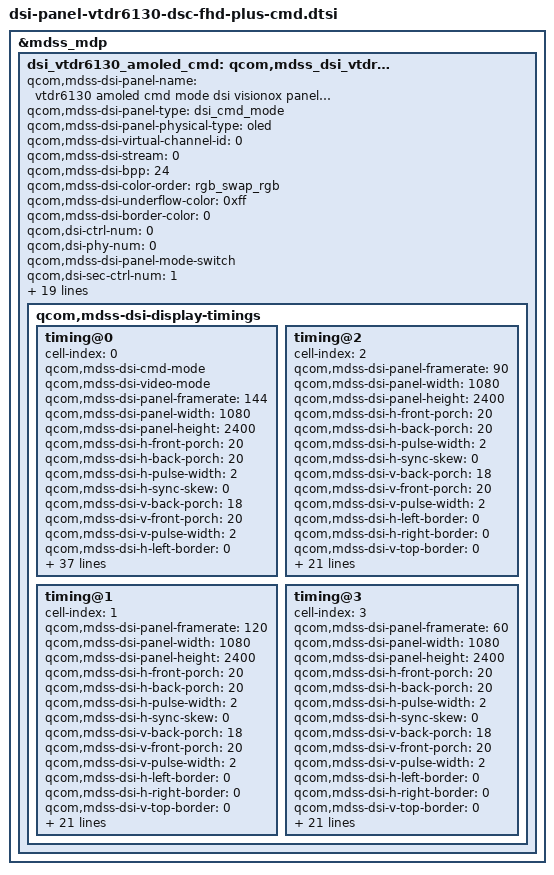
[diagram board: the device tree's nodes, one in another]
&mdss_mdp {
	dsi_vtdr6130_amoled_cmd: qcom,mdss_dsi_vtdr6130_fhd_plus_cmd {
		qcom,mdss-dsi-panel-name =
			"vtdr6130 amoled cmd mode dsi visionox panel with DSC";
		qcom,mdss-dsi-panel-type = "dsi_cmd_mode";
		qcom,mdss-dsi-panel-physical-type = "oled";
		qcom,mdss-dsi-virtual-channel-id = <0>;
		qcom,mdss-dsi-stream = <0>;
		qcom,mdss-dsi-bpp = <24>;
		qcom,mdss-dsi-color-order = "rgb_swap_rgb";
		qcom,mdss-dsi-underflow-color = <0xff>;
		qcom,mdss-dsi-border-color = <0>;

		qcom,dsi-ctrl-num = <0>;
		qcom,dsi-phy-num = <0>;
		qcom,mdss-dsi-panel-mode-switch;

		qcom,dsi-sec-ctrl-num = <1>;
		qcom,dsi-sec-phy-num = <1>;

		qcom,mdss-dsi-traffic-mode = "non_burst_sync_event";
		qcom,mdss-dsi-lane-map = "lane_map_0123";
		qcom,mdss-dsi-bllp-eof-power-mode;
		qcom,mdss-dsi-bllp-power-mode;
		qcom,mdss-dsi-lane-0-state;
		qcom,mdss-dsi-lane-1-state;
		qcom,mdss-dsi-lane-2-state;
		qcom,mdss-dsi-lane-3-state;
		qcom,mdss-dsi-dma-trigger = "trigger_sw";
		qcom,mdss-dsi-mdp-trigger = "none";
		qcom,mdss-dsi-reset-sequence = <1 10>, <0 10>, <1 10>;

		qcom,mdss-dsi-te-pin-select = <1>;
		qcom,mdss-dsi-wr-mem-start = <0x2c>;
		qcom,mdss-dsi-wr-mem-continue = <0x3c>;
		qcom,mdss-dsi-te-dcs-command = <1>;
		qcom,mdss-dsi-te-check-enable;
		qcom,mdss-dsi-te-using-te-pin;
		qcom,mdss-dsi-display-timings {
			timing@0 {
				cell-index = <0>;
				qcom,mdss-dsi-cmd-mode;
				qcom,mdss-dsi-video-mode;
				qcom,mdss-dsi-panel-framerate = <144>;
				qcom,mdss-dsi-panel-width = <1080>;
				qcom,mdss-dsi-panel-height = <2400>;
				qcom,mdss-dsi-h-front-porch = <20>;
				qcom,mdss-dsi-h-back-porch = <20>;
				qcom,mdss-dsi-h-pulse-width = <2>;
				qcom,mdss-dsi-h-sync-skew = <0>;
				qcom,mdss-dsi-v-back-porch = <18>;
				qcom,mdss-dsi-v-front-porch = <20>;
				qcom,mdss-dsi-v-pulse-width = <2>;
				qcom,mdss-dsi-h-left-border = <0>;
				qcom,mdss-dsi-h-right-border = <0>;
				qcom,mdss-dsi-v-top-border = <0>;
				qcom,mdss-dsi-v-bottom-border = <0>;
				qcom,mdss-dsi-panel-jitter = <0x4 0x1>;
				qcom,mdss-dsi-panel-clockrate = <847480320>;

				qcom,mdss-dsi-timing-switch-command = [
					39 01 00 00 00 00 02 6c 01
					39 01 00 00 00 00 03 f0 aa 10
					39 01 00 00 00 00 16 b1 01 38 00 14 00
					   1c 00 01 66 00 14 00 14 00 01 66 00
					   14 05 cc 00
					39 01 00 00 00 00 03 f0 aa 13
					39 01 00 00 00 00 18 ce 09 11 09 11 08
					   c1 07 fa 05 a4 00 3c 00 34 00 24 00
					   0c 00 0c 04 00 35
				];

				qcom,cmd-on-commands = [
					39 01 00 00 00 00 02 03 01
					39 01 00 00 00 00 02 35 00
					39 01 00 00 00 00 02 53 20
					39 01 00 00 00 00 03 51 00 00
					39 01 00 00 00 00 02 59 00
					39 01 00 00 00 00 02 6c 01
					39 01 00 00 00 00 02 6d 00
					39 01 00 00 00 00 02 6f 02
					39 01 00 00 00 00 5f 70 12 00 00 ab 30
					   80 09 60 04 38 00 28 02 1c 02 1c 02
					   00 02 0e 00 20 03 dd 00 07 00 0c 02
					   77 02 8b 18 00 10 f0 07 10 20 00 06
					   0f 0f 33 0e 1c 2a 38 46 54 62 69 70
					   77 79 7b 7d 7e 02 02 22 00 2a 40 2a
					   be 3a fc 3a fa 3a f8 3b 38 3b 78 3b
					   b6 4b b6 4b f4 4b f4 6c 34 84 74 00
					   00 00 00 00 00
					39 01 00 00 00 00 03 f0 aa 10
					39 01 00 00 00 00 02 65 16
					39 01 00 00 00 00 03 EB 00 00
					39 01 00 00 00 00 16 b1 01 38 00 14 00
					   1c 00 01 66 00 14 00 14 00 01 66 00
					   14 05 cc 00
					39 01 00 00 00 00 03 f0 aa 13
					39 01 00 00 00 00 18 ce 09 11 09 11 08
					   c1 07 fa 05 a4 00 3c 00 34 00 24 00
					   0c 00 0c 04 00 35
					39 01 00 00 00 00 03 f0 aa 14
					39 01 00 00 00 00 03 b2 03 33
					39 01 00 00 00 00 0d b4 00 33 00 00 00
					   3e 00 00 00 3e 00 00
					39 01 00 00 00 00 0a b5 00 09 09 09 09
					   09 09 06 01
					39 01 00 00 00 00 07 b9 00 00 08 09 09
					   09
					39 01 00 00 00 00 0d bc 10 00 00 06 11
					   09 3b 09 47 09 47 00
					39 01 00 00 00 00 0d be 10 10 00 08 22
					   09 19 09 25 09 25 00
					39 01 00 00 00 00 03 ff 5a 80
					39 01 00 00 00 00 02 65 14
					39 01 00 00 00 00 04 fa 08 08 08
					39 01 00 00 00 00 03 ff 5a 81
					39 01 00 00 00 00 02 65 05
					39 01 00 00 00 00 02 f3 0f
					39 01 00 00 00 00 03 f0 aa 00
					39 01 00 00 00 00 03 ff 5a 82
					39 01 00 00 00 00 02 f9 00
					39 01 00 00 00 00 03 ff 51 83
					39 01 00 00 00 00 02 65 04
					39 01 00 00 00 00 02 f8 00
					39 01 00 00 00 00 03 ff 5a 00
					39 01 00 00 00 00 02 65 01
					39 01 00 00 00 00 02 f4 9a
					39 01 00 00 00 00 03 ff 5a 00
					05 01 00 00 78 00 01 11
					05 01 00 00 14 00 01 29
				];

				qcom,vid-on-commands = [
					39 01 00 00 00 00 02 03 01
					39 01 00 00 00 00 02 35 00
					39 01 00 00 00 00 02 53 20
					39 01 00 00 00 00 03 51 00 00
					39 01 00 00 00 00 02 59 00
					39 01 00 00 00 00 02 6C 01
					39 01 00 00 00 00 02 6D 00
					39 01 00 00 00 00 02 6F 01
					39 01 00 00 00 00 5F 70 12 00 00 AB 30
					   80 09 60 04 38 00 28 02 1C 02 1C 02
					   00 02 0E 00 20 03 DD 00 07 00 0C 02
					   77 02 8B 18 00 10 F0 07 10 20 00 06
					   0F 0F 33 0E 1C 2A 38 46 54 62 69 70
					   77 79 7B 7D 7E 02 02 22 00 2A 40 2A
					   BE 3A FC 3A FA 3A F8 3B 38 3B 78 3B
					   B6 4B B6 4B F4 4B F4 6C 34 84 74 00
					   00 00 00 00 00
					39 01 00 00 00 00 03 F0 AA 10
					39 01 00 00 00 00 02 65 16
					39 01 00 00 00 00 03 EB 00 00
					39 01 00 00 00 00 16 B1 01 38 00 14 00
					   1C 00 01 66 00 14 00 14 00 01 66 00
					   14 05 CC 00
					39 01 00 00 00 00 03 F0 AA 13
					39 01 00 00 00 00 18 CE 09 11 09 11 08
					   C1 07 FA 05 A4 00 3C 00 34 00 24 00
					   0C 00 0C 04 00 35
					39 01 00 00 00 00 03 F0 AA 14
					39 01 00 00 00 00 03 B2 03 33
					39 01 00 00 00 00 0D B4 00 33 00 00 00
					   3E 00 00 00 3E 00 00
					39 01 00 00 00 00 0A B5 00 09 09 09 09
					   09 09 06 01
					39 01 00 00 00 00 07 B9 00 00 08 09 09
					   09
					39 01 00 00 00 00 0D BC 10 00 00 06 11
					   09 3B 09 47 09 47 00
					39 01 00 00 00 00 0D BE 10 10 00 08 22
					   09 19 09 25 09 25 00
					39 01 00 00 00 00 03 FF 5A 80
					39 01 00 00 00 00 02 65 14
					39 01 00 00 00 00 04 FA 08 08 08
					39 01 00 00 00 00 03 FF 5A 81
					39 01 00 00 00 00 02 65 05
					39 01 00 00 00 00 02 F3 0F
					39 01 00 00 00 00 03 F0 AA 00
					39 01 00 00 00 00 03 FF 5A 82
					39 01 00 00 00 00 02 F9 00
					39 01 00 00 00 00 03 FF 51 83
					39 01 00 00 00 00 02 65 04
					39 01 00 00 00 00 02 F8 00
					39 01 00 00 00 00 03 FF 5A 00
					39 01 00 00 00 00 02 65 01
					39 01 00 00 00 00 02 F4 9A
					39 01 00 00 00 00 03 FF 5A 00
					05 01 00 00 78 00 01 11
					05 01 00 00 14 00 01 29
				];

				qcom,mdss-dsi-off-command = [
					05 01 00 00 14 00 02 28 00
					05 01 00 00 78 00 02 10 00];
				qcom,mdss-dsi-on-command-state = "dsi_lp_mode";
				qcom,mdss-dsi-off-command-state = "dsi_hs_mode";

				qcom,cmd-mode-switch-out-commands = [
					39 01 00 00 00 00 02 6f 07
				];
				qcom,cmd-mode-switch-out-commands-state =
					"dsi_lp_mode";

				qcom,video-mode-switch-in-commands = [
					39 01 00 00 00 00 02 6f 01
				];
				qcom,video-mode-switch-in-commands-state =
					"dsi_lp_mode";

				qcom,video-mode-switch-out-commands = [
					39 01 00 00 00 00 02 6f 03
					39 01 00 00 00 00 02 6f 02
				];
				qcom,video-mode-switch-out-commands-state =
					"dsi_lp_mode";

				qcom,mdss-dsi-timing-switch-command-state =
					"dsi_lp_mode";
				qcom,mdss-dsi-h-sync-pulse = <0>;
				qcom,compression-mode = "dsc";
				qcom,mdss-dsc-slice-height = <40>;
				qcom,mdss-dsc-slice-width = <540>;
				qcom,mdss-dsc-slice-per-pkt = <1>;
				qcom,mdss-dsc-bit-per-component = <8>;
				qcom,mdss-dsc-bit-per-pixel = <8>;
				qcom,mdss-dsc-block-prediction-enable;
			};

			timing@1 {
				cell-index = <1>;
				qcom,mdss-dsi-panel-framerate = <120>;
				qcom,mdss-dsi-panel-width = <1080>;
				qcom,mdss-dsi-panel-height = <2400>;
				qcom,mdss-dsi-h-front-porch = <20>;
				qcom,mdss-dsi-h-back-porch = <20>;
				qcom,mdss-dsi-h-pulse-width = <2>;
				qcom,mdss-dsi-h-sync-skew = <0>;
				qcom,mdss-dsi-v-back-porch = <18>;
				qcom,mdss-dsi-v-front-porch = <20>;
				qcom,mdss-dsi-v-pulse-width = <2>;
				qcom,mdss-dsi-h-left-border = <0>;
				qcom,mdss-dsi-h-right-border = <0>;
				qcom,mdss-dsi-v-top-border = <0>;
				qcom,mdss-dsi-v-bottom-border = <0>;
				qcom,mdss-dsi-panel-jitter = <0x4 0x1>;
				qcom,mdss-dsi-panel-clockrate = <847480320>;

				qcom,mdss-dsi-timing-switch-command = [
					39 01 00 00 00 00 02 6c 01
					39 01 00 00 00 00 03 f0 aa 10
					39 01 00 00 00 00 16 b1 01 38 00 14 00
					   1c 00 01 66 00 14 01 fc 00 01 66 00
					   14 0d 6c 00
					39 01 00 00 00 00 03 f0 aa 13
					39 01 00 00 00 00 18 ce 0a e1 0a e1 0a
					   81 09 92 06 c5 00 48 00 3e 00 2b 00
					   0c 00 0c 05 00 3f
				];

				qcom,mdss-dsi-on-command = [
					39 01 00 00 00 00 02 03 01
					39 01 00 00 00 00 02 35 00
					39 01 00 00 00 00 02 53 20
					39 01 00 00 00 00 03 51 00 00
					39 01 00 00 00 00 02 59 00
					39 01 00 00 00 00 02 6c 01
					39 01 00 00 00 00 02 6d 00
					39 01 00 00 00 00 02 6f 02
					39 01 00 00 00 00 5f 70 12 00 00 ab 30
					   80 09 60 04 38 00 28 02 1c 02 1c 02
					   00 02 0e 00 20 03 dd 00 07 00 0c 02
					   77 02 8b 18 00 10 f0 07 10 20 00 06
					   0f 0f 33 0e 1c 2a 38 46 54 62 69 70
					   77 79 7b 7d 7e 02 02 22 00 2a 40 2a
					   be 3a fc 3a fa 3a f8 3b 38 3b 78 3b
					   b6 4b b6 4b f4 4b f4 6c 34 84 74 00
					   00 00 00 00 00
					39 01 00 00 00 00 03 f0 aa 10
					39 01 00 00 00 00 02 65 16
					39 01 00 00 00 00 03 EB 00 00
					39 01 00 00 00 00 16 b1 01 38 00 14 00
					   1c 00 01 66 00 14 01 fc 00 01 66 00
					   14 0d 6c 00
					39 01 00 00 00 00 03 f0 aa 13
					39 01 00 00 00 00 18 ce 0a e1 0a e1 0a
					   81 09 92 06 c5 00 48 00 3e 00 2b 00
					   0c 00 0c 05 00 3f
					39 01 00 00 00 00 03 f0 aa 14
					39 01 00 00 00 00 03 b2 03 33
					39 01 00 00 00 00 0d b4 00 33 00 00 00
					   3e 00 00 00 3e 00 00
					39 01 00 00 00 00 0a b5 00 09 09 09 09
					   09 09 06 01
					39 01 00 00 00 00 07 b9 00 00 08 09 09
					   09
					39 01 00 00 00 00 0d bc 10 00 00 06 11
					   09 3b 09 47 09 47 00
					39 01 00 00 00 00 0d be 10 10 00 08 22
					   09 19 09 25 09 25 00
					39 01 00 00 00 00 03 ff 5a 80
					39 01 00 00 00 00 02 65 14
					39 01 00 00 00 00 04 fa 08 08 08
					39 01 00 00 00 00 03 ff 5a 81
					39 01 00 00 00 00 02 65 05
					39 01 00 00 00 00 02 f3 0f
					39 01 00 00 00 00 03 f0 aa 00
					39 01 00 00 00 00 03 ff 5a 82
					39 01 00 00 00 00 02 f9 00
					39 01 00 00 00 00 03 ff 51 83
					39 01 00 00 00 00 02 65 04
					39 01 00 00 00 00 02 f8 00
					39 01 00 00 00 00 03 ff 5a 00
					39 01 00 00 00 00 02 65 01
					39 01 00 00 00 00 02 f4 9a
					39 01 00 00 00 00 03 ff 5a 00
					05 01 00 00 78 00 01 11
					05 01 00 00 14 00 01 29
				];

				qcom,mdss-dsi-off-command = [
					05 01 00 00 14 00 02 28 00
					05 01 00 00 78 00 02 10 00];
				qcom,mdss-dsi-on-command-state = "dsi_lp_mode";
				qcom,mdss-dsi-off-command-state = "dsi_hs_mode";
				qcom,mdss-dsi-timing-switch-command-state =
					"dsi_lp_mode";
				qcom,mdss-dsi-h-sync-pulse = <0>;
				qcom,compression-mode = "dsc";
				qcom,mdss-dsc-slice-height = <40>;
				qcom,mdss-dsc-slice-width = <540>;
				qcom,mdss-dsc-slice-per-pkt = <1>;
				qcom,mdss-dsc-bit-per-component = <8>;
				qcom,mdss-dsc-bit-per-pixel = <8>;
				qcom,mdss-dsc-block-prediction-enable;
			};

			timing@2 {
				cell-index = <2>;
				qcom,mdss-dsi-panel-framerate = <90>;
				qcom,mdss-dsi-panel-width = <1080>;
				qcom,mdss-dsi-panel-height = <2400>;
				qcom,mdss-dsi-h-front-porch = <20>;
				qcom,mdss-dsi-h-back-porch = <20>;
				qcom,mdss-dsi-h-pulse-width = <2>;
				qcom,mdss-dsi-h-sync-skew = <0>;
				qcom,mdss-dsi-v-back-porch = <18>;
				qcom,mdss-dsi-v-front-porch = <20>;
				qcom,mdss-dsi-v-pulse-width = <2>;
				qcom,mdss-dsi-h-left-border = <0>;
				qcom,mdss-dsi-h-right-border = <0>;
				qcom,mdss-dsi-v-top-border = <0>;
				qcom,mdss-dsi-v-bottom-border = <0>;
				qcom,mdss-dsi-panel-jitter = <0x4 0x1>;
				qcom,mdss-dsi-panel-clockrate = <847480320>;

				qcom,mdss-dsi-timing-switch-command = [
					39 01 00 00 00 00 02 6c 02
					39 01 00 00 00 00 03 f0 aa 10
					39 01 00 00 00 00 16 b1 01 38 00 14 00
					   1c 00 01 66 00 14 00 14 00 01 66 00
					   14 05 cc 00
					39 01 00 00 00 00 03 f0 aa 13
					39 01 00 00 00 00 18 d3 0e 81 0e 81 0e
					   01 0c c3 09 06 00 60 00 53 00 3a 00
					   0c 00 0c 07 00 54
				];

				qcom,mdss-dsi-on-command = [
					39 01 00 00 00 00 02 03 01
					39 01 00 00 00 00 02 35 00
					39 01 00 00 00 00 02 53 20
					39 01 00 00 00 00 03 51 00 00
					39 01 00 00 00 00 02 59 00
					39 01 00 00 00 00 02 6c 02
					39 01 00 00 00 00 02 6d 00
					39 01 00 00 00 00 02 6f 02
					39 01 00 00 00 00 5f 70 12 00 00 ab 30
					   80 09 60 04 38 00 28 02 1c 02 1c 02
					   00 02 0e 00 20 03 dd 00 07 00 0c 02
					   77 02 8b 18 00 10 f0 07 10 20 00 06
					   0f 0f 33 0e 1c 2a 38 46 54 62 69 70
					   77 79 7b 7d 7e 02 02 22 00 2a 40 2a
					   be 3a fc 3a fa 3a f8 3b 38 3b 78 3b
					   b6 4b b6 4b f4 4b f4 6c 34 84 74 00
					   00 00 00 00 00
					39 01 00 00 00 00 03 f0 aa 10
					39 01 00 00 00 00 02 65 16
					39 01 00 00 00 00 03 EB 00 00
					39 01 00 00 00 00 16 b1 01 38 00 14 00
					   1c 00 01 66 00 14 00 14 00 01 66 00
					   14 05 cc 00
					39 01 00 00 00 00 03 f0 aa 13
					39 01 00 00 00 00 18 d3 0e 81 0e 81 0e
					   01 0c c3 09 06 00 60 00 53 00 3a 00
					   0c 00 0c 07 00 54
					39 01 00 00 00 00 03 f0 aa 14
					39 01 00 00 00 00 03 b2 03 33
					39 01 00 00 00 00 0d b4 00 33 00 00 00
					   3e 00 00 00 3e 00 00
					39 01 00 00 00 00 0a b5 00 09 09 09 09
					   09 09 06 01
					39 01 00 00 00 00 07 b9 00 00 08 09 09
					   09
					39 01 00 00 00 00 0d bc 10 00 00 06 11
					   09 3b 09 47 09 47 00
					39 01 00 00 00 00 0d be 10 10 00 08 22
					   09 19 09 25 09 25 00
					39 01 00 00 00 00 03 ff 5a 80
					39 01 00 00 00 00 02 65 14
					39 01 00 00 00 00 04 fa 08 08 08
					39 01 00 00 00 00 03 ff 5a 81
					39 01 00 00 00 00 02 65 05
					39 01 00 00 00 00 02 f3 0f
					39 01 00 00 00 00 03 f0 aa 00
					39 01 00 00 00 00 03 ff 5a 82
					39 01 00 00 00 00 02 f9 00
					39 01 00 00 00 00 03 ff 51 83
					39 01 00 00 00 00 02 65 04
					39 01 00 00 00 00 02 f8 00
					39 01 00 00 00 00 03 ff 5a 00
					39 01 00 00 00 00 02 65 01
					39 01 00 00 00 00 02 f4 9a
					39 01 00 00 00 00 03 ff 5a 00
					05 01 00 00 78 00 01 11
					05 01 00 00 14 00 01 29
				];

				qcom,mdss-dsi-off-command = [
					05 01 00 00 14 00 02 28 00
					05 01 00 00 78 00 02 10 00];
				qcom,mdss-dsi-on-command-state = "dsi_lp_mode";
				qcom,mdss-dsi-off-command-state = "dsi_hs_mode";
				qcom,mdss-dsi-timing-switch-command-state =
					"dsi_lp_mode";
				qcom,mdss-dsi-h-sync-pulse = <0>;
				qcom,compression-mode = "dsc";
				qcom,mdss-dsc-slice-height = <40>;
				qcom,mdss-dsc-slice-width = <540>;
				qcom,mdss-dsc-slice-per-pkt = <1>;
				qcom,mdss-dsc-bit-per-component = <8>;
				qcom,mdss-dsc-bit-per-pixel = <8>;
				qcom,mdss-dsc-block-prediction-enable;
			};

			timing@3 {
				cell-index = <3>;
				qcom,mdss-dsi-panel-framerate = <60>;
				qcom,mdss-dsi-panel-width = <1080>;
				qcom,mdss-dsi-panel-height = <2400>;
				qcom,mdss-dsi-h-front-porch = <20>;
				qcom,mdss-dsi-h-back-porch = <20>;
				qcom,mdss-dsi-h-pulse-width = <2>;
				qcom,mdss-dsi-h-sync-skew = <0>;
				qcom,mdss-dsi-v-back-porch = <18>;
				qcom,mdss-dsi-v-front-porch = <20>;
				qcom,mdss-dsi-v-pulse-width = <2>;
				qcom,mdss-dsi-h-left-border = <0>;
				qcom,mdss-dsi-h-right-border = <0>;
				qcom,mdss-dsi-v-top-border = <0>;
				qcom,mdss-dsi-v-bottom-border = <0>;
				qcom,mdss-dsi-panel-jitter = <0x4 0x1>;
				qcom,mdss-dsi-panel-clockrate = <847480320>;

				qcom,mdss-dsi-timing-switch-command = [
					39 01 00 00 00 00 02 6c 02
					39 01 00 00 00 00 03 f0 aa 10
					39 01 00 00 00 00 16 b1 01 38 00 14 00
					   1c 00 01 66 00 14 01 fc 00 01 66 00
					   14 0d 6c 00
					39 01 00 00 00 00 03 f0 aa 13
					39 01 00 00 00 00 18 d3 15 c2 15 c2 15
					   02 13 25 0d 8a 00 90 00 7d 00 57 00
					   0c 00 0c 0b 00 7e
				];

				qcom,mdss-dsi-on-command = [
					39 01 00 00 00 00 02 03 01
					39 01 00 00 00 00 02 35 00
					39 01 00 00 00 00 02 53 20
					39 01 00 00 00 00 03 51 00 00
					39 01 00 00 00 00 02 59 00
					39 01 00 00 00 00 02 6c 02
					39 01 00 00 00 00 02 6d 00
					39 01 00 00 00 00 02 6f 02
					39 01 00 00 00 00 5f 70 12 00 00 ab 30
					   80 09 60 04 38 00 28 02 1c 02 1c 02
					   00 02 0e 00 20 03 dd 00 07 00 0c 02
					   77 02 8b 18 00 10 f0 07 10 20 00 06
					   0f 0f 33 0e 1c 2a 38 46 54 62 69 70
					   77 79 7b 7d 7e 02 02 22 00 2a 40 2a
					   be 3a fc 3a fa 3a f8 3b 38 3b 78 3b
					   b6 4b b6 4b f4 4b f4 6c 34 84 74 00
					   00 00 00 00 00
					39 01 00 00 00 00 03 f0 aa 10
					39 01 00 00 00 00 02 65 16
					39 01 00 00 00 00 03 EB 00 00
					39 01 00 00 00 00 16 b1 01 38 00 14 00
					   1c 00 01 66 00 14 01 fc 00 01 66 00
					   14 0d 6c 00
					39 01 00 00 00 00 03 f0 aa 13
					39 01 00 00 00 00 18 d3 15 c2 15 c2 15
					   02 13 25 0d 8a 00 90 00 7d 00 57 00
					   0c 00 0c 0b 00 7e
					39 01 00 00 00 00 03 f0 aa 14
					39 01 00 00 00 00 03 b2 03 33
					39 01 00 00 00 00 0d b4 00 33 00 00 00
					   3e 00 00 00 3e 00 00
					39 01 00 00 00 00 0a b5 00 09 09 09 09
					   09 09 06 01
					39 01 00 00 00 00 07 b9 00 00 08 09 09
					   09
					39 01 00 00 00 00 0d bc 10 00 00 06 11
					   09 3b 09 47 09 47 00
					39 01 00 00 00 00 0d be 10 10 00 08 22
					   09 19 09 25 09 25 00
					39 01 00 00 00 00 03 ff 5a 80
					39 01 00 00 00 00 02 65 14
					39 01 00 00 00 00 04 fa 08 08 08
					39 01 00 00 00 00 03 ff 5a 81
					39 01 00 00 00 00 02 65 05
					39 01 00 00 00 00 02 f3 0f
					39 01 00 00 00 00 03 f0 aa 00
					39 01 00 00 00 00 03 ff 5a 82
					39 01 00 00 00 00 02 f9 00
					39 01 00 00 00 00 03 ff 51 83
					39 01 00 00 00 00 02 65 04
					39 01 00 00 00 00 02 f8 00
					39 01 00 00 00 00 03 ff 5a 00
					39 01 00 00 00 00 02 65 01
					39 01 00 00 00 00 02 f4 9a
					39 01 00 00 00 00 03 ff 5a 00
					05 01 00 00 78 00 01 11
					05 01 00 00 14 00 01 29
				];

				qcom,mdss-dsi-off-command = [
					05 01 00 00 14 00 02 28 00
					05 01 00 00 78 00 02 10 00];
				qcom,mdss-dsi-on-command-state = "dsi_lp_mode";
				qcom,mdss-dsi-off-command-state = "dsi_hs_mode";
				qcom,mdss-dsi-timing-switch-command-state =
					"dsi_lp_mode";
				qcom,mdss-dsi-h-sync-pulse = <0>;
				qcom,compression-mode = "dsc";
				qcom,mdss-dsc-slice-height = <40>;
				qcom,mdss-dsc-slice-width = <540>;
				qcom,mdss-dsc-slice-per-pkt = <1>;
				qcom,mdss-dsc-bit-per-component = <8>;
				qcom,mdss-dsc-bit-per-pixel = <8>;
				qcom,mdss-dsc-block-prediction-enable;
			};
		};
	};
};
